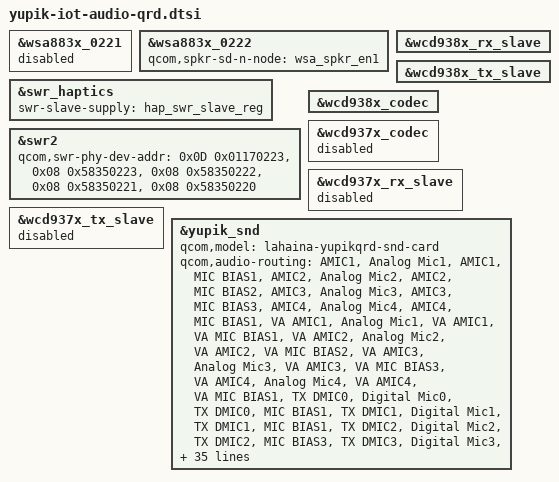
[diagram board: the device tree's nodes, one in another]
// SPDX-License-Identifier: BSD-3-Clause
/*
 * Changes from Qualcomm Technologies, Inc. are provided under the following license:
 * Copyright (c) Qualcomm Technologies, Inc. and/or its subsidiaries.
 */

#include "yupik-iot-audio-overlay.dtsi"


&wsa883x_0221 {
        status = "disabled";
};

&wsa883x_0222 {
        qcom,spkr-sd-n-node = <&wsa_spkr_en1>;
};

&swr_haptics {
        status = "okay";
        swr-slave-supply = <&hap_swr_slave_reg>;
};

&swr2 {
        qcom,swr-phy-dev-addr = <0x0D 0x01170223>,
                                <0x08 0x58350223>,
                                <0x08 0x58350222>,
                                <0x08 0x58350221>,
                                <0x08 0x58350220>;
};

&wcd938x_rx_slave {
        status = "okay";
};

&wcd938x_tx_slave {
        status = "okay";
};

&wcd938x_codec {
        status = "okay";
};

&wcd937x_codec {
        status = "disabled";
};

&wcd937x_rx_slave {
        status = "disabled";
};

&wcd937x_tx_slave {
        status = "disabled";
};

&yupik_snd {
        qcom,model = "lahaina-yupikqrd-snd-card";
	qcom,audio-routing =
		"AMIC1", "Analog Mic1",
		"AMIC1", "MIC BIAS1",
		"AMIC2", "Analog Mic2",
		"AMIC2", "MIC BIAS2",
		"AMIC3", "Analog Mic3",
		"AMIC3", "MIC BIAS3",
		"AMIC4", "Analog Mic4",
		"AMIC4", "MIC BIAS1",
		"VA AMIC1", "Analog Mic1",
		"VA AMIC1", "VA MIC BIAS1",
		"VA AMIC2", "Analog Mic2",
		"VA AMIC2", "VA MIC BIAS2",
		"VA AMIC3", "Analog Mic3",
		"VA AMIC3", "VA MIC BIAS3",
		"VA AMIC4", "Analog Mic4",
		"VA AMIC4", "VA MIC BIAS1",
		"TX DMIC0", "Digital Mic0",
		"TX DMIC0", "MIC BIAS1",
		"TX DMIC1", "Digital Mic1",
		"TX DMIC1", "MIC BIAS1",
		"TX DMIC2", "Digital Mic2",
		"TX DMIC2", "MIC BIAS3",
		"TX DMIC3", "Digital Mic3",
		"TX DMIC3", "MIC BIAS3",
		"TX DMIC5", "Digital Mic5",
		"TX DMIC5", "MIC BIAS4",
		"IN1_HPHL", "HPHL_OUT",
		"IN2_HPHR", "HPHR_OUT",
		"IN3_AUX", "AUX_OUT",
		"HAP_IN", "PCM_OUT",
		"WSA SRC0_INP", "SRC0",
		"WSA_TX DEC0_INP", "TX DEC0 MUX",
		"WSA_TX DEC1_INP", "TX DEC1 MUX",
		"RX_TX DEC0_INP", "TX DEC0 MUX",
		"RX_TX DEC1_INP", "TX DEC1 MUX",
		"RX_TX DEC2_INP", "TX DEC2 MUX",
		"RX_TX DEC3_INP", "TX DEC3 MUX",
		"SpR IN", "WSA_SPK2 OUT",
		"TX SWR_INPUT", "WCD_TX_OUTPUT",
		"VA SWR_INPUT", "VA_SWR_CLK",
		"VA SWR_INPUT", "WCD_TX_OUTPUT",
		"VA_AIF1 CAP", "VA_SWR_CLK",
		"VA_AIF2 CAP", "VA_SWR_CLK",
		"VA_AIF3 CAP", "VA_SWR_CLK",
		"VA DMIC0", "Digital Mic0",
		"VA DMIC1", "Digital Mic1",
		"VA DMIC2", "Digital Mic2",
		"VA DMIC3", "Digital Mic3",
		"VA DMIC4", "Digital Mic4",
		"VA DMIC5", "Digital Mic5",
		"VA DMIC0", "VA MIC BIAS1",
		"VA DMIC1", "VA MIC BIAS3",
		"VA DMIC2", "VA MIC BIAS4",
		"VA DMIC3", "VA MIC BIAS1",
		"VA DMIC4", "VA MIC BIAS3",
		"VA DMIC5", "VA MIC BIAS4";
        qcom,swr-dmic-max-devs = <0>;

        qcom,msm-mbhc-usbc-audio-supported = <1>;
        qcom,msm-mbhc-hphl-swh = <0>;
        qcom,msm-mbhc-gnd-swh = <0>;

        asoc-codec  = <&stub_codec>, <&bolero>,
                      <&wcd938x_codec>, <&swr_haptics>,
                      <&wsa883x_0222>,
                      <&ext_disp_audio_codec>;
        asoc-codec-names = "msm-stub-codec.1", "bolero_codec",
                           "wcd938x_codec", "swr-haptics",
                           "wsa-codec2",
                           "msm-ext-disp-audio-codec-rx";
        qcom,wsa-max-devs = <1>;
        qcom,msm_audio_ssr_devs = <&audio_gpr>, <&lpi_tlmm>,
                                  <&bolero>;
};
